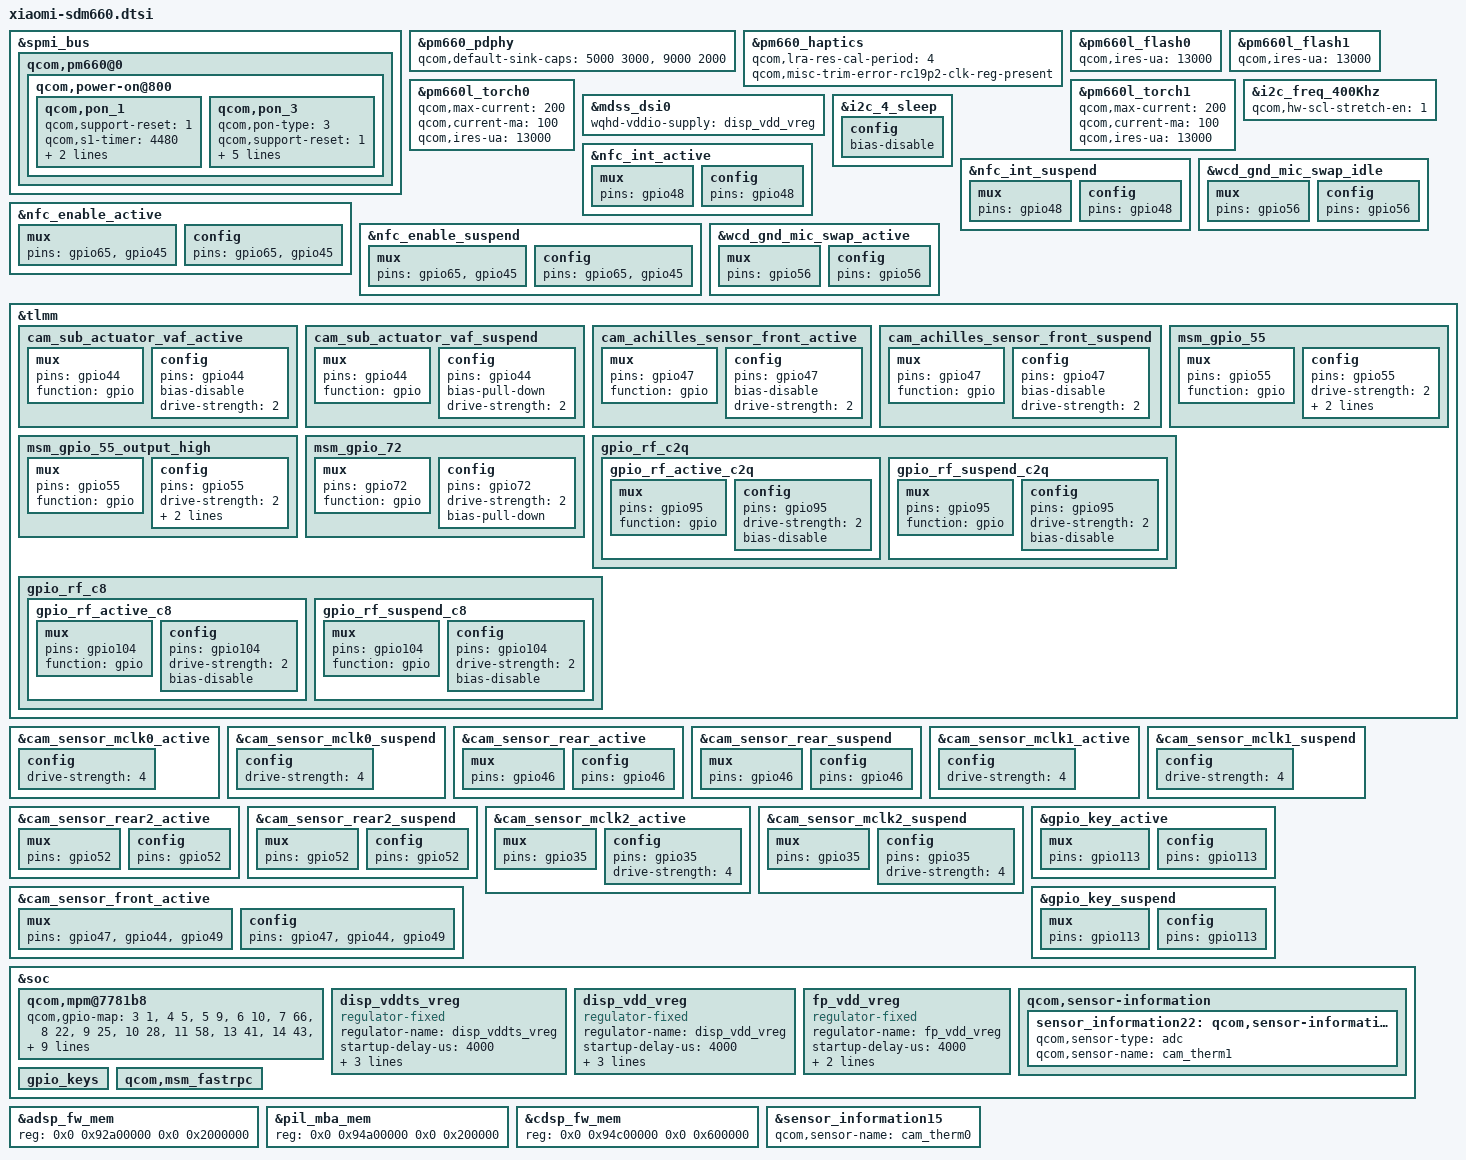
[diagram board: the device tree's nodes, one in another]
/* Copyright (c) 2016-2017, The Linux Foundation. All rights reserved.
 * Copyright (C) 2017 XiaoMi, Inc.
 *
 * This program is free software; you can redistribute it and/or modify
 * it under the terms of the GNU General Public License version 2 and
 * only version 2 as published by the Free Software Foundation.
 *
 * This program is distributed in the hope that it will be useful,
 * but WITHOUT ANY WARRANTY; without even the implied warranty of
 * MERCHANTABILITY or FITNESS FOR A PARTICULAR PURPOSE.  See the
 * GNU General Public License for more details.
 */

#include "jason-sdm660-mdss-panels.dtsi"

// msm-pm660.dtsi
&spmi_bus {
	qcom,pm660@0 {
		qcom,power-on@800 {
			qcom,pon_1 {
				qcom,support-reset = <1>;
				qcom,s1-timer = <4480>;
				qcom,s2-timer = <2000>;
				qcom,s2-type = <7>;
			};

			qcom,pon_3 {
				qcom,pon-type = <3>;
				qcom,support-reset = <1>;
				qcom,pull-up = <1>;
				qcom,s1-timer = <1352>;
				qcom,s2-timer = <2000>;
				qcom,s2-type = <1>;
				qcom,use-bark;
			};
		};
	};
};

&pm660_pdphy {
	qcom,default-sink-caps = <5000 3000>, /* 5V @ 3A */
				<9000 2000>; /* 9V @ 2A */
};

&pm660_haptics {
	qcom,lra-res-cal-period = <4>;
	qcom,misc-trim-error-rc19p2-clk-reg-present;
};

// msm-pm660l.dtsi
&pm660l_flash0 {
	qcom,ires-ua = <13000>;
};

&pm660l_flash1 {
	qcom,ires-ua = <13000>;
};

&pm660l_torch0 {
	qcom,max-current = <200>;
	qcom,current-ma = <100>;
	qcom,ires-ua = <13000>;
};

&pm660l_torch1 {
	qcom,max-current = <200>;
	qcom,current-ma = <100>;
	qcom,ires-ua = <13000>;
};

// sdm660-camera.dtsi
&i2c_freq_400Khz {
	qcom,hw-scl-stretch-en = <1>;
};

// sdm660-mdss.dtsi
&mdss_dsi0 {
	wqhd-vddio-supply = <&disp_vdd_vreg>;
};

// sdm660-pinctrl.dtsi
&i2c_4_sleep {
	config {
		/delete-property/ bias-pull-up;
		bias-disable;
	};
};

&nfc_int_active {
	mux {
		/* GPIO 48 NFC Read Interrupt */
		pins = "gpio48";
	};

	config {
		pins = "gpio48";
	};
};

&nfc_int_suspend {
	mux {
		/* GPIO 48 NFC Read Interrupt */
		pins = "gpio48";
	};

	config {
		pins = "gpio48";
	};
};

&nfc_enable_active {
	mux {
		/* 65: NFC ENABLE */
		/* 45:ESE Enable */
		pins = "gpio65", "gpio45";
	};

	config {
		pins = "gpio65", "gpio45";
	};
};

&nfc_enable_suspend {
	mux {
		/* 65: NFC ENABLE */
		/* 45:ESE Enable */
		pins = "gpio65", "gpio45";
	};

	config {
		pins = "gpio65", "gpio45";
	};
};

&wcd_gnd_mic_swap_idle {
	mux {
		pins = "gpio56";
	};
	config {
		pins = "gpio56";
	};
};

&wcd_gnd_mic_swap_active {
	mux {
		pins = "gpio56";
	};
	config {
		pins = "gpio56";
	};
};

&tlmm {
	cam_sub_actuator_vaf_active: cam_sub_actuator_vaf_active {
		/* ACTUATOR POWER */
		mux {
			pins = "gpio44";
			function = "gpio";
		};

		config {
			pins = "gpio44";
			bias-disable; /* No PULL */
			drive-strength = <2>; /* 2 MA */
		};
	};

	cam_sub_actuator_vaf_suspend: cam_sub_actuator_vaf_suspend {
		/* ACTUATOR POWER */
		mux {
			pins = "gpio44";
			function = "gpio";
		};

		config {
			pins = "gpio44";
			bias-pull-down; /* PULL DOWN */
			drive-strength = <2>; /* 2 MA */
		};
	};
};

&cam_sensor_mclk0_active {
	config {
		drive-strength = <4>; /* 4 MA */
	};
};

&cam_sensor_mclk0_suspend {
	config {
		drive-strength = <4>; /* 4 MA */
	};
};

&cam_sensor_rear_active {
	mux {
		pins = "gpio46";
	};

	config {
		pins = "gpio46";
	};
};

&cam_sensor_rear_suspend {
	mux {
		pins = "gpio46";
	};

	config {
		pins = "gpio46";
	};
};

&cam_sensor_mclk1_active {
	config {
		drive-strength = <4>; /* 4 MA */
	};
};

&cam_sensor_mclk1_suspend {
	config {
		drive-strength = <4>; /* 4 MA */
	};
};

&cam_sensor_rear2_active {
	mux {
		pins = "gpio52";
	};

	config {
		pins = "gpio52";
	};
};

&cam_sensor_rear2_suspend {
	mux {
		pins = "gpio52";
	};

	config {
		pins = "gpio52";
	};
};

&cam_sensor_mclk2_active {
	mux {
		/* CLK, DATA */
		pins = "gpio35";
	};

	config {
		pins = "gpio35";
		drive-strength = <4>; /* 4 MA */
	};
};

&cam_sensor_mclk2_suspend {
	mux {
		/* CLK, DATA */
		pins = "gpio35";
	};

	config {
		pins = "gpio35";
		drive-strength = <4>; /* 4 MA */
	};
};

&cam_sensor_front_active {
	mux {
		/* RESET STANBY VANA*/
		pins = "gpio47", "gpio44", "gpio49";
	};

	config {
		pins = "gpio47", "gpio44", "gpio49";
	};
};

&tlmm {
	cam_achilles_sensor_front_active: cam_achilles_sensor_front_active {
		/* RESET STANBY VANA*/
		mux {
			pins = "gpio47";
			function = "gpio";
		};

		config {
			pins = "gpio47";
			bias-disable; /* No PULL */
			drive-strength = <2>; /* 2 MA */
		};
	};

	cam_achilles_sensor_front_suspend: cam_achilles_sensor_front_suspend {
		/* RESET */
		mux {
			pins = "gpio47";
			function = "gpio";
		};

		config {
			pins = "gpio47";
			bias-disable; /* No PULL */
			drive-strength = <2>; /* 2 MA */
		};
	};
};

&gpio_key_active {
	mux {
		pins = "gpio113";
	};

	config {
		pins = "gpio113";
	};
};

&gpio_key_suspend {
	mux {
		pins = "gpio113";
	};

	config {
		pins = "gpio113";
	};
};

&tlmm {
	/* GPIO_55 : FP_RESET_N */
	msm_gpio_55: msm_gpio_55 {
		mux {
			pins = "gpio55";
			function = "gpio";
		};

		config {
			pins = "gpio55";
			drive-strength = <2>;
			bias-disable;
			output-low;
		};
	};

	/* GPIO_55 : FP_RESET_N, state device active*/
	msm_gpio_55_output_high: msm_gpio_55_output_high {
		mux {
			pins = "gpio55";
			function = "gpio";
		};

		config {
			pins = "gpio55";
			drive-strength = <2>;
			bias-disable;
			output-high;
		};
	};

	/* GPIO_72 : FP_INT_N */
	msm_gpio_72: msm_gpio_72 {
		mux {
			pins = "gpio72";
			function = "gpio";
		};

		config {
			pins = "gpio72";
			drive-strength = <2>;
			bias-pull-down;
		};
	};

	gpio_rf_c2q {
		gpio_rf_active_c2q: gpio_rf_active_c2q {
			mux {
				pins = "gpio95";
				function = "gpio";
			};
			config {
				pins = "gpio95";
				drive-strength = <2>;
				bias-disable;
			};
		};
			gpio_rf_suspend_c2q: gpio_rf_suspend_c2q {
			mux {
				pins = "gpio95";
				function = "gpio";
			};
			config {
				pins = "gpio95";
				drive-strength = <2>;
				bias-disable;
			};
		};
	};

	gpio_rf_c8 {
		gpio_rf_active_c8: gpio_rf_active_c8 {
			mux {
				pins = "gpio104";
				function = "gpio";
			};
			config {
				pins = "gpio104";
				drive-strength = <2>;
				bias-disable;
			};
		};
			gpio_rf_suspend_c8: gpio_rf_suspend_c8 {
			mux {
				pins = "gpio104";
				function = "gpio";
			};
			config {
				pins = "gpio104";
				drive-strength = <2>;
				bias-disable;
			};
		};
	};
};

// sdm660-pm.dtsi
&soc {
	qcom,mpm@7781b8 {
		qcom,gpio-map =
			<3  1>,
			<4  5>,
			<5  9>,
			<6  10>,
			<7  66>,
			<8  22>,
			<9  25>,
			<10  28>,
			<11  58>,
			<13  41>,
			<14  43>,
			<15  40>,
			<16  42>,
			<17  46>,
			<18  50>,
			<19  44>,
			<21  56>,
			<22  45>,
			<23  68>,
			<24  69>,
			<25  70>,
			<26  71>,
			<27  72>,
			<28  73>,
			<29  64>,
			<30  2>,
			<31  13>,
			<32  111>,
			<33  74>,
			<34  75>,
			<35  76>,
			<36  82>,
			<37  17>,
			<38  77>,
			<39  47>,
			<40  54>,
			<41  48>,
			<42  101>,
			<43  49>,
			<44  51>,
			<45  86>,
			<46  90>,
			<47  91>,
			<48  52>,
			<50  55>,
			<51  6>,
			<53  65>,
			<55  67>,
			<56  83>,
			<57  84>,
			<58  85>,
			<59  87>,
			<60  104>,
			<63  21>,
			<64  78>,
			<65  113>,
			<66  60>,
			<67  98>,
			<68  30>,
			<70  31>,
			<71  29>,
			<76  107>,
			<83  109>,
			<84  103>,
			<85  105>;
	};
};

// sdm660-regulator.dtsi
&soc {
	disp_vddts_vreg: disp_vddts_vreg {
		compatible = "regulator-fixed";
		regulator-name = "disp_vddts_vreg";
		startup-delay-us = <4000>;
		enable-active-high;
		regulator-boot-on;
		gpio = <&tlmm 73 0>;
	};

	disp_vdd_vreg: disp_vdd_vreg {
		compatible = "regulator-fixed";
		regulator-name = "disp_vdd_vreg";
		startup-delay-us = <4000>;
		enable-active-high;
		regulator-boot-on;
		gpio = <&tlmm 62 0>;
	};

	fp_vdd_vreg: fp_vdd_vreg {
		compatible = "regulator-fixed";
		regulator-name = "fp_vdd_vreg";
		startup-delay-us = <4000>;
		enable-active-high;
		gpio = <&tlmm 64 0>;
	};
};

// sdm660.dtsi
&adsp_fw_mem {
	reg = <0x0 0x92a00000 0x0 0x2000000>;
};

&pil_mba_mem {
	reg = <0x0 0x94a00000 0x0 0x200000>;
};

&cdsp_fw_mem {
	reg = <0x0 0x94c00000 0x0 0x600000>;
};

&sensor_information15 {
	qcom,sensor-name = "cam_therm0";
};

&soc {
	qcom,sensor-information {
		sensor_information22: qcom,sensor-information-22 {
			qcom,sensor-type =  "adc";
			qcom,sensor-name = "cam_therm1";
		};
	};

	gpio_keys {
		/delete-node/ camera_focus;
		/delete-node/ camera_snapshot;
	};

	qcom,msm_fastrpc {
		/delete-property/ qcom,fastrpc-vmid-heap-shared;
	};
};
